# ing920 register map
Vendor: INGChips; Series: ing920xx; File version: 1.0
CPU: CM3 r2p1, little endian, no MPU, no FPU, 2 interrupt priority bits
Registers are 32-bit, read-write, reset 0x0 unless marked. A register's access mark holds for its fields unless they carry their own. Offsets are from the block's base; [hi:lo] are bit positions; {n}, {i} and the like mark numbered series.

## sys_ctrl
Base 0x40000000
0x00 cgu_cfg0 — reg description:
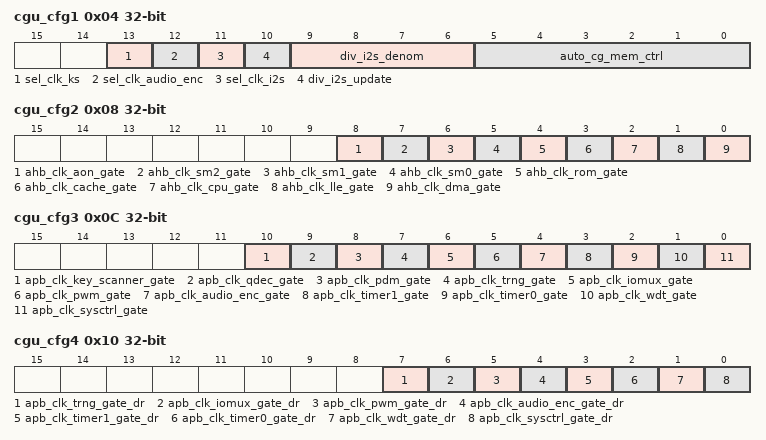
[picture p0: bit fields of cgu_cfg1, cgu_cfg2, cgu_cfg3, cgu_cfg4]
0x04 cgu_cfg1 — reg description:
  [13] sel_clk_ks — reg description:
  [12] sel_clk_audio_enc — reg description:
  [11] sel_clk_i2s — reg description:
  [10] div_i2s_update — reg description:
  [9:6] div_i2s_denom — reg description:
  [5:0] auto_cg_mem_ctrl — reg description:
0x08 cgu_cfg2 — reg description:
  [8] ahb_clk_aon_gate — reg description:
  [7] ahb_clk_sm2_gate — reg description:
  [6] ahb_clk_sm1_gate — reg description:
  [5] ahb_clk_sm0_gate — reg description:
  [4] ahb_clk_rom_gate — reg description:
  [3] ahb_clk_cache_gate — reg description:
  [2] ahb_clk_cpu_gate — reg description:
  [1] ahb_clk_lle_gate — reg description:
  [0] ahb_clk_dma_gate — reg description:
0x0C cgu_cfg3 — reg description:
  [10] apb_clk_key_scanner_gate — reg description:
  [9] apb_clk_qdec_gate — reg description:
  [8] apb_clk_pdm_gate — reg description:
  [7] apb_clk_trng_gate — reg description:
  [6] apb_clk_iomux_gate — reg description:
  [5] apb_clk_pwm_gate — reg description:
  [4] apb_clk_audio_enc_gate — reg description:
  [3] apb_clk_timer1_gate — reg description:
  [2] apb_clk_timer0_gate — reg description:
  [1] apb_clk_wdt_gate — reg description:
  [0] apb_clk_sysctrl_gate — reg description:
0x10 cgu_cfg4 — reg description:
  [7] apb_clk_trng_gate_dr — reg description:
  [6] apb_clk_iomux_gate_dr — reg description:
  [5] apb_clk_pwm_gate_dr — reg description:
  [4] apb_clk_audio_enc_gate_dr — reg description:
  [3] apb_clk_timer1_gate_dr — reg description:
  [2] apb_clk_timer0_gate_dr — reg description:
  [1] apb_clk_wdt_gate_dr — reg description:
  [0] apb_clk_sysctrl_gate_dr — reg description:
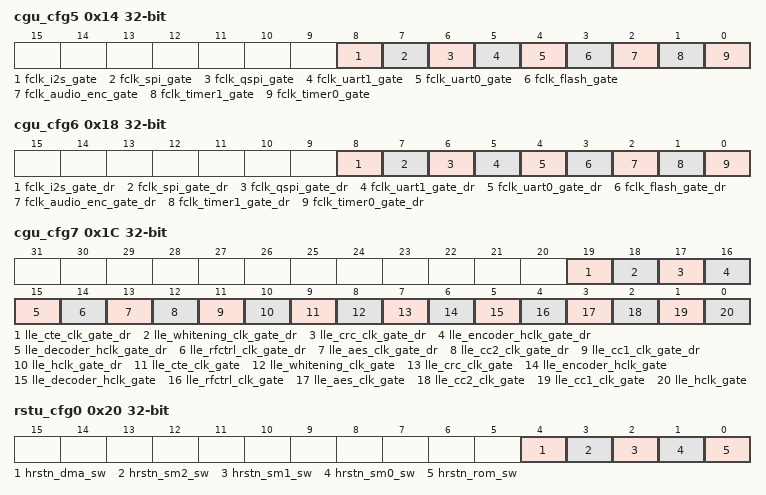
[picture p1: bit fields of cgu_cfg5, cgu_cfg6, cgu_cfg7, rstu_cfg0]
0x14 cgu_cfg5 — reg description:
  [8] fclk_i2s_gate — reg description:
  [7] fclk_spi_gate — reg description:
  [6] fclk_qspi_gate — reg description:
  [5] fclk_uart1_gate — reg description:
  [4] fclk_uart0_gate — reg description:
  [3] fclk_flash_gate — reg description:
  [2] fclk_audio_enc_gate — reg description:
  [1] fclk_timer1_gate — reg description:
  [0] fclk_timer0_gate — reg description:
0x18 cgu_cfg6 — reg description:
  [8] fclk_i2s_gate_dr — reg description:
  [7] fclk_spi_gate_dr — reg description:
  [6] fclk_qspi_gate_dr — reg description:
  [5] fclk_uart1_gate_dr — reg description:
  [4] fclk_uart0_gate_dr — reg description:
  [3] fclk_flash_gate_dr — reg description:
  [2] fclk_audio_enc_gate_dr — reg description:
  [1] fclk_timer1_gate_dr — reg description:
  [0] fclk_timer0_gate_dr — reg description:
0x1C cgu_cfg7 — reg description:
  [19] lle_cte_clk_gate_dr — reg description:
  [18] lle_whitening_clk_gate_dr — reg description:
  [17] lle_crc_clk_gate_dr — reg description:
  [16] lle_encoder_hclk_gate_dr — reg description:
  [15] lle_decoder_hclk_gate_dr — reg description:
  [14] lle_rfctrl_clk_gate_dr — reg description:
  [13] lle_aes_clk_gate_dr — reg description:
  [12] lle_cc2_clk_gate_dr — reg description:
  [11] lle_cc1_clk_gate_dr — reg description:
  [10] lle_hclk_gate_dr — reg description:
  [9] lle_cte_clk_gate — reg description:
  [8] lle_whitening_clk_gate — reg description:
  [7] lle_crc_clk_gate — reg description:
  [6] lle_encoder_hclk_gate — reg description:
  [5] lle_decoder_hclk_gate — reg description:
  [4] lle_rfctrl_clk_gate — reg description:
  [3] lle_aes_clk_gate — reg description:
  [2] lle_cc2_clk_gate — reg description:
  [1] lle_cc1_clk_gate — reg description:
  [0] lle_hclk_gate — reg description:
0x20 rstu_cfg0 — reg description:
  [4] hrstn_dma_sw — reg description:
  [3] hrstn_sm2_sw — reg description:
  [2] hrstn_sm1_sw — reg description:
  [1] hrstn_sm0_sw — reg description:
  [0] hrstn_rom_sw — reg description:
0x24 rstu_cfg1 — reg description:
  [0] prstn_gpio1_sw
0x28 sys_ctrl_0 — reg description:
  [0] sel_sys_dcachen
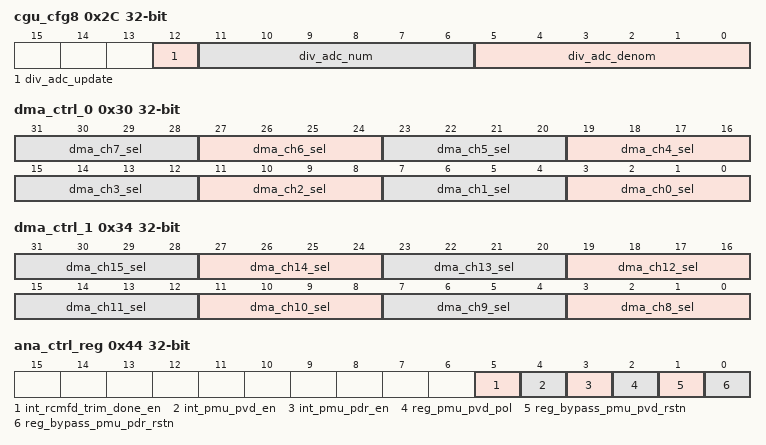
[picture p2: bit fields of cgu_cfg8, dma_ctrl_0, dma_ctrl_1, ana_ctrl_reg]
0x2C cgu_cfg8 — reg description:
  [12] div_adc_update — reg description:
  [11:6] div_adc_num — reg description:
  [5:0] div_adc_denom — reg description:
0x30 dma_ctrl_0 — reg description:
  [4n+3:4n] dma_ch{n}_sel (n=0..7) — reg description:
0x34 dma_ctrl_1 — reg description:
  [4n-29:4n-32] dma_ch{n}_sel (n=8..15) — reg description:
0x40 pll_ctrl_reg — reg description:
0x44 ana_ctrl_reg — reg description:
  [5] int_rcmfd_trim_done_en — reg description:
  [4] int_pmu_pvd_en — reg description:
  [3] int_pmu_pdr_en — reg description:
  [2] reg_pmu_pvd_pol — reg description:
  [1] reg_bypass_pmu_pvd_rstn — reg description:
  [0] reg_bypass_pmu_pdr_rstn — reg description:
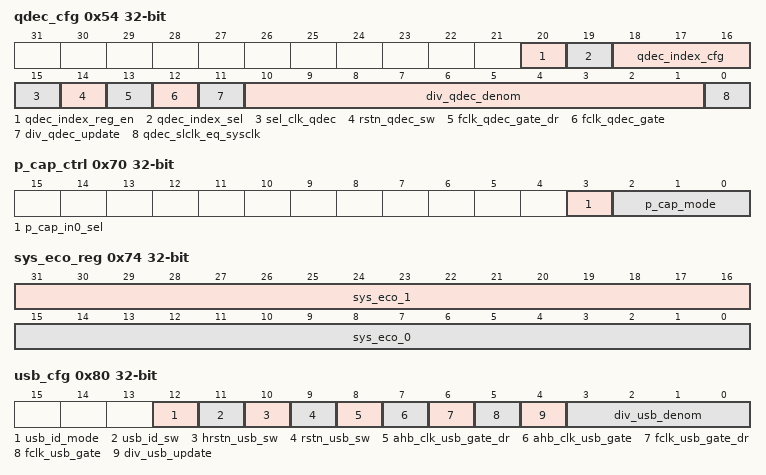
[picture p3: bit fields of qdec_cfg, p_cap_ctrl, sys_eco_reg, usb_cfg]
0x54 qdec_cfg — reg description:
  [20] qdec_index_reg_en — reg description:
  [19] qdec_index_sel — reg description:
  [18:16] qdec_index_cfg — reg description:
  [15] sel_clk_qdec — reg description:
  [14] rstn_qdec_sw — reg description:
  [13] fclk_qdec_gate_dr — reg description:
  [12] fclk_qdec_gate — reg description:
  [11] div_qdec_update — reg description:
  [10:1] div_qdec_denom — reg description:
  [0] qdec_slclk_eq_sysclk — reg description:
0x60 sys_io_status — reg description:
0x64 sys_io_wk_source — reg description:
  [31:0] sys_io_wk_source_lsb
0x68 sys_io_in_status — reg description:
  [31:0] io_in_lsb
0x70 p_cap_ctrl — reg description:
  [3] p_cap_in0_sel — reg description:
  [2:0] p_cap_mode — reg description:
0x74 sys_eco_reg — reg description:
  [31:16] sys_eco_1 — reg description:
  [15:0] sys_eco_0 — reg description:
0x7C sys_lock — reg description:
  [0] lock_sw
0x80 usb_cfg — reg description:
  [12] usb_id_mode — reg description:
  [11] usb_id_sw — reg description:
  [10] hrstn_usb_sw — reg description:
  [9] rstn_usb_sw — reg description:
  [8] ahb_clk_usb_gate_dr — reg description:
  [7] ahb_clk_usb_gate — reg description:
  [6] fclk_usb_gate_dr — reg description:
  [5] fclk_usb_gate — reg description:
  [4] div_usb_update — reg description:
  [3:0] div_usb_denom — reg description:
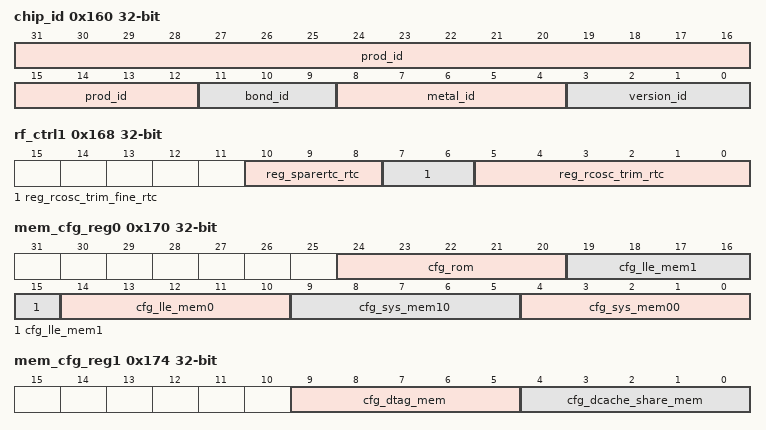
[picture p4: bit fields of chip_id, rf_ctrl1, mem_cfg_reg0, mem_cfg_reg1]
0x160 chip_id — reg description:
  [31:12] prod_id — reg description:
  [11:9] bond_id — reg description:
  [8:4] metal_id — reg description:
  [3:0] version_id — reg description:
0x164 rf_ctrl0 — reg description:
0x168 rf_ctrl1 — reg description:
  [10:8] reg_sparertc_rtc — reg description:
  [7:6] reg_rcosc_trim_fine_rtc — reg description:
  [5:0] reg_rcosc_trim_rtc — reg description:
0x170 mem_cfg_reg0 — reg description:
  [24:20] cfg_rom — reg description:
  [19:15] cfg_lle_mem1 — reg description:
  [14:10] cfg_lle_mem0 — reg description:
  [9:5] cfg_sys_mem10 — reg description:
  [4:0] cfg_sys_mem00 — reg description:
0x174 mem_cfg_reg1 — reg description:
  [9:5] cfg_dtag_mem — reg description:
  [4:0] cfg_dcache_share_mem — reg description:
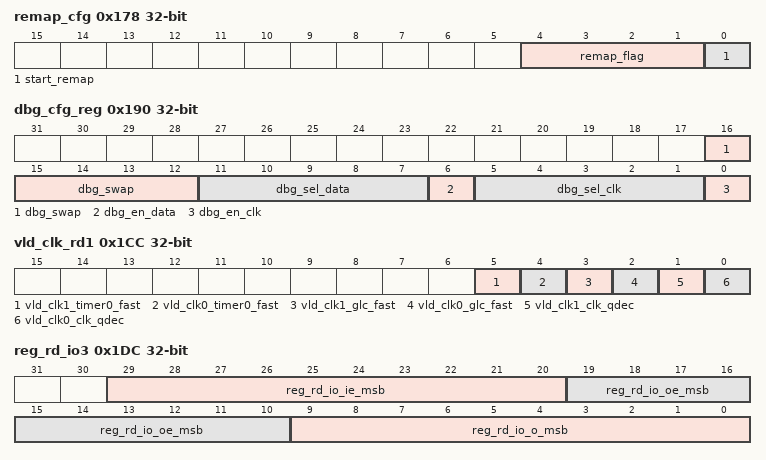
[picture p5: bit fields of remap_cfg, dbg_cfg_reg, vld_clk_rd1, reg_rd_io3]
0x178 remap_cfg — reg description:
  [4:1] remap_flag — reg description:
  [0] start_remap — reg description:
0x190 dbg_cfg_reg — reg description:
  [16:12] dbg_swap — reg description:
  [11:7] dbg_sel_data — reg description:
  [6] dbg_en_data — reg description:
  [5:1] dbg_sel_clk — reg description:
  [0] dbg_en_clk — reg description:
0x1C4 io_vdd_ok — reg description:
  [0] sys_io_vddok
0x1C8 vld_clk_rd — reg description:
0x1CC vld_clk_rd1 — reg description:
  [5] vld_clk1_timer0_fast — reg description:
  [4] vld_clk0_timer0_fast — reg description:
  [3] vld_clk1_glc_fast — reg description:
  [2] vld_clk0_glc_fast — reg description:
  [1] vld_clk1_clk_qdec — reg description:
  [0] vld_clk0_clk_qdec — reg description:
0x1D0 reg_rd_io0 — reg description:
  [31:0] reg_rd_io_o_lsb
0x1D4 reg_rd_io1 — reg description:
  [31:0] reg_rd_io_oe_lsb
0x1D8 reg_rd_io2 — reg description:
  [31:0] reg_rd_io_ie_lsb
0x1DC reg_rd_io3 — reg description:
  [29:20] reg_rd_io_ie_msb — reg description:
  [19:10] reg_rd_io_oe_msb — reg description:
  [9:0] reg_rd_io_o_msb — reg description:
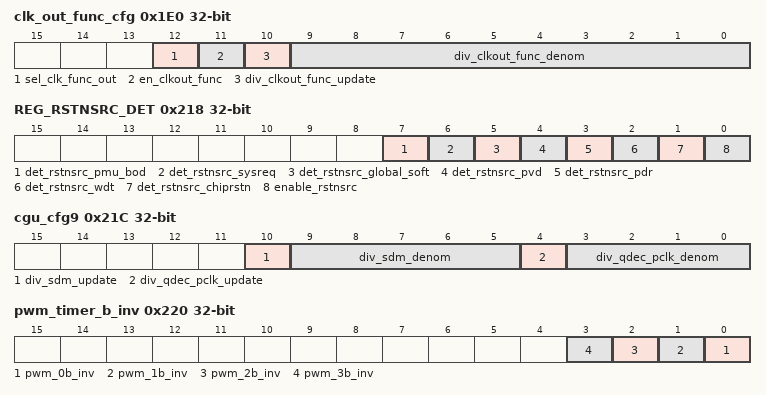
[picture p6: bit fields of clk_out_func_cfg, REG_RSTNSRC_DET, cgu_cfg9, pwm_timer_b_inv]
0x1E0 clk_out_func_cfg — reg description:
  [12] sel_clk_func_out — reg description:
  [11] en_clkout_func — reg description:
  [10] div_clkout_func_update — reg description:
  [9:0] div_clkout_func_denom — reg description:
{0x1F0+4i} REG_GPIOTE_CONFIG{i} (i=0..7) — reg description:
  [1:0] gpiote_config{i}_mode
0x210 REG_DLY_CHAIN_EN — reg description:
  [0] dly_count_en
0x214 REG_DLY_CHAIN_CNT — reg description:
  [31:0] dly_cnt
0x218 REG_RSTNSRC_DET — reg description:
  [7] det_rstnsrc_pmu_bod — reg description:
  [6] det_rstnsrc_sysreq — reg description:
  [5] det_rstnsrc_global_soft — reg description:
  [4] det_rstnsrc_pvd — reg description:
  [3] det_rstnsrc_pdr — reg description:
  [2] det_rstnsrc_wdt — reg description:
  [1] det_rstnsrc_chiprstn — reg description:
  [0] enable_rstnsrc — reg description:
0x21C cgu_cfg9 — reg description:
  [10] div_sdm_update — reg description:
  [9:5] div_sdm_denom — reg description:
  [4] div_qdec_pclk_update — reg description:
  [3:0] div_qdec_pclk_denom — reg description:
0x220 pwm_timer_b_inv — reg description:
  [n] pwm_{n}b_inv (n=0..3) — reg description:
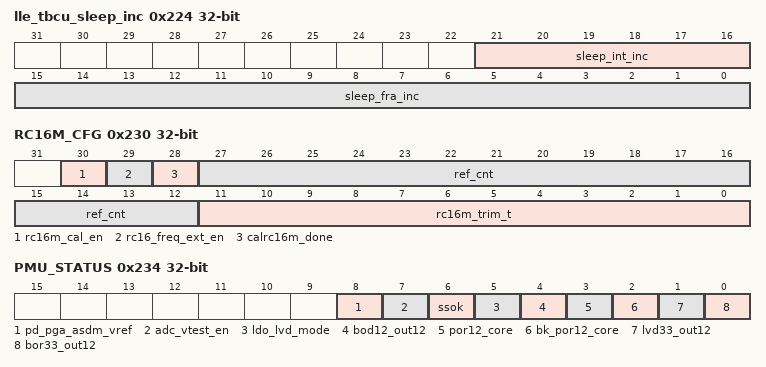
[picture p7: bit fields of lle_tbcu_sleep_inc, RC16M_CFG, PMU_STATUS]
0x224 lle_tbcu_sleep_inc — reg description:
  [21:16] sleep_int_inc — reg description:
  [15:0] sleep_fra_inc — reg description:
0x230 RC16M_CFG — reg description:
  [30] rc16m_cal_en — reg description:
  [29] rc16_freq_ext_en — reg description:
  [28] calrc16m_done — reg description:
  [27:12] ref_cnt — reg description:
  [11:0] rc16m_trim_t — reg description:
0x234 PMU_STATUS — reg description:
  [8] pd_pga_asdm_vref — reg description:
  [7] adc_vtest_en — reg description:
  [6] ssok — reg description:
  [5] ldo_lvd_mode — reg description:
  [4] bod12_out12 — reg description:
  [3] por12_core — reg description:
  [2] bk_por12_core — reg description:
  [1] lvd33_out12 — reg description:
  [0] bor33_out12 — reg description:
